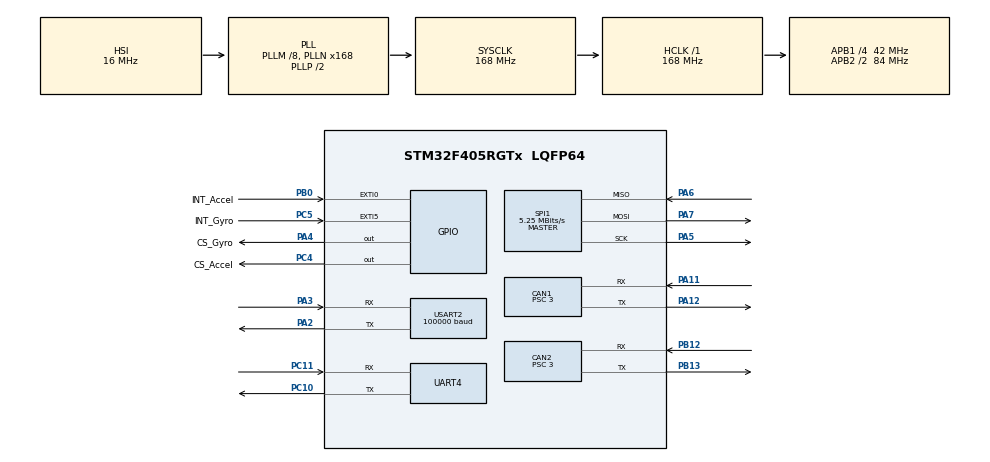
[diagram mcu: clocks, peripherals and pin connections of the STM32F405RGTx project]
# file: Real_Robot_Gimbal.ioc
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CAN1.ABOM=ENABLE
CAN1.AWUM=ENABLE
CAN1.AutoBusOff=ENABLE
CAN1.AutoRetransmission=ENABLE
CAN1.BS1=CAN_BS1_10TQ
CAN1.BS2=CAN_BS2_3TQ
CAN1.CalculateBaudRate=1000000
CAN1.CalculateTimeBit=1000
CAN1.CalculateTimeQuantum=71.42857142857143
CAN1.NART=ENABLE
CAN1.Prescaler=3
CAN1.SJW=CAN_SJW_2TQ
CAN2.AutoBusOff=ENABLE
CAN2.AutoRetransmission=ENABLE
CAN2.BS1=CAN_BS1_10TQ
CAN2.BS2=CAN_BS2_3TQ
CAN2.CalculateBaudRate=1000000
CAN2.CalculateTimeBit=1000
CAN2.CalculateTimeQuantum=71.42857142857143
CAN2.Prescaler=3
CAN2.SJW=CAN_SJW_2TQ
Dma.Request0=USART2_RX
Dma.Request1=USART2_TX
Dma.Request2=SPI1_RX
Dma.Request3=UART4_RX
Dma.Request4=UART4_TX
Dma.Request5=SPI1_TX
Dma.SPI1_RX.2.Direction=DMA_PERIPH_TO_MEMORY
Dma.SPI1_RX.2.FIFOMode=DMA_FIFOMODE_DISABLE
Dma.SPI1_RX.2.Instance=DMA2_Stream0
Dma.SPI1_RX.2.MemDataAlignment=DMA_MDATAALIGN_BYTE
Dma.SPI1_RX.2.MemInc=DMA_MINC_ENABLE
Dma.SPI1_RX.2.Mode=DMA_NORMAL
Dma.SPI1_RX.2.PeriphDataAlignment=DMA_PDATAALIGN_BYTE
Dma.SPI1_RX.2.PeriphInc=DMA_PINC_DISABLE
Dma.SPI1_RX.2.Priority=DMA_PRIORITY_LOW
Dma.SPI1_TX.5.Direction=DMA_MEMORY_TO_PERIPH
Dma.SPI1_TX.5.FIFOMode=DMA_FIFOMODE_DISABLE
Dma.SPI1_TX.5.Instance=DMA2_Stream3
Dma.SPI1_TX.5.MemDataAlignment=DMA_MDATAALIGN_BYTE
Dma.SPI1_TX.5.MemInc=DMA_MINC_ENABLE
Dma.SPI1_TX.5.Mode=DMA_NORMAL
Dma.SPI1_TX.5.PeriphDataAlignment=DMA_PDATAALIGN_BYTE
Dma.SPI1_TX.5.PeriphInc=DMA_PINC_DISABLE
Dma.SPI1_TX.5.Priority=DMA_PRIORITY_LOW
Dma.UART4_RX.3.Direction=DMA_PERIPH_TO_MEMORY
Dma.UART4_RX.3.FIFOMode=DMA_FIFOMODE_DISABLE
Dma.UART4_RX.3.Instance=DMA1_Stream2
Dma.UART4_RX.3.MemDataAlignment=DMA_MDATAALIGN_BYTE
Dma.UART4_RX.3.MemInc=DMA_MINC_ENABLE
Dma.UART4_RX.3.Mode=DMA_NORMAL
Dma.UART4_RX.3.PeriphDataAlignment=DMA_PDATAALIGN_BYTE
Dma.UART4_RX.3.PeriphInc=DMA_PINC_DISABLE
Dma.UART4_RX.3.Priority=DMA_PRIORITY_LOW
Dma.UART4_TX.4.Direction=DMA_MEMORY_TO_PERIPH
Dma.UART4_TX.4.FIFOMode=DMA_FIFOMODE_DISABLE
Dma.UART4_TX.4.Instance=DMA1_Stream4
Dma.UART4_TX.4.MemDataAlignment=DMA_MDATAALIGN_BYTE
Dma.UART4_TX.4.MemInc=DMA_MINC_ENABLE
Dma.UART4_TX.4.Mode=DMA_NORMAL
Dma.UART4_TX.4.PeriphDataAlignment=DMA_PDATAALIGN_BYTE
Dma.UART4_TX.4.PeriphInc=DMA_PINC_DISABLE
Dma.UART4_TX.4.Priority=DMA_PRIORITY_LOW
Dma.USART2_RX.0.Direction=DMA_PERIPH_TO_MEMORY
Dma.USART2_RX.0.FIFOMode=DMA_FIFOMODE_DISABLE
Dma.USART2_RX.0.Instance=DMA1_Stream5
Dma.USART2_RX.0.MemDataAlignment=DMA_MDATAALIGN_BYTE
Dma.USART2_RX.0.MemInc=DMA_MINC_ENABLE
Dma.USART2_RX.0.Mode=DMA_NORMAL
Dma.USART2_RX.0.PeriphDataAlignment=DMA_PDATAALIGN_BYTE
Dma.USART2_RX.0.PeriphInc=DMA_PINC_DISABLE
Dma.USART2_RX.0.Priority=DMA_PRIORITY_LOW
Dma.USART2_TX.1.Direction=DMA_MEMORY_TO_PERIPH
Dma.USART2_TX.1.FIFOMode=DMA_FIFOMODE_DISABLE
Dma.USART2_TX.1.Instance=DMA1_Stream6
Dma.USART2_TX.1.MemDataAlignment=DMA_MDATAALIGN_BYTE
Dma.USART2_TX.1.MemInc=DMA_MINC_ENABLE
Dma.USART2_TX.1.Mode=DMA_NORMAL
Dma.USART2_TX.1.PeriphDataAlignment=DMA_PDATAALIGN_BYTE
Dma.USART2_TX.1.PeriphInc=DMA_PINC_DISABLE
Dma.USART2_TX.1.Priority=DMA_PRIORITY_LOW
FREERTOS.BinarySemaphores01=wake_launch,Dynamic,NULL,Not Available;wake_launch_motor,Dynamic,NULL,Not Available
FREERTOS.Queues01=Target_Angle,8,TargetAngleMessage_t,0,Dynamic,NULL,NULL;Update_PID_para,8,PidParameterUpdate_t,0,Dynamic,NULL,NULL;Update_launch_para,4,LaunchParameterUpdate_t,0,Dynamic,NULL,NULL
FREERTOS.Tasks01=defaultTask,24,128,StartDefaultTask,Default,NULL,Dynamic,NULL,NULL;Process_Data,9,512,Data_Process,As weak,NULL,Dynamic,NULL,NULL;PID,24,512,PID_calc,As weak,NULL,Dynamic,NULL,NULL;vofa,8,256,VOFA_print,As weak,NULL,Dynamic,NULL,NULL;launch,24,128,Launch_Task,As weak,NULL,Dynamic,NULL,NULL
Mcu.Family=STM32F4
Mcu.Name=STM32F405RGTx
Mcu.Package=LQFP64
NVIC.CAN1_RX0_IRQn=true\:5\:0\:false\:false\:true\:true\:true\:true\:true
NVIC.CAN2_RX0_IRQn=true\:5\:0\:false\:false\:true\:true\:true\:true\:true
NVIC.DMA1_Stream2_IRQn=true\:5\:0\:false\:false\:true\:true\:false\:true\:true
NVIC.DMA1_Stream4_IRQn=true\:5\:0\:false\:false\:true\:true\:false\:true\:true
NVIC.DMA1_Stream5_IRQn=true\:5\:0\:false\:false\:true\:true\:false\:true\:true
NVIC.DMA1_Stream6_IRQn=true\:5\:0\:false\:false\:true\:true\:false\:true\:true
NVIC.DMA2_Stream0_IRQn=true\:5\:0\:false\:false\:true\:true\:false\:true\:true
NVIC.DMA2_Stream3_IRQn=true\:5\:0\:false\:false\:true\:true\:false\:true\:true
NVIC.EXTI0_IRQn=true\:5\:0\:false\:false\:true\:true\:true\:true\:true
NVIC.EXTI9_5_IRQn=true\:5\:0\:false\:false\:true\:true\:true\:true\:true
NVIC.PriorityGroup=NVIC_PRIORITYGROUP_4
NVIC.TIM1_UP_TIM10_IRQn=true\:15\:0\:false\:false\:true\:false\:false\:true\:true
NVIC.TimeBase=TIM1_UP_TIM10_IRQn
NVIC.TimeBaseIP=TIM1
NVIC.UART4_IRQn=true\:5\:0\:false\:false\:true\:true\:false\:true\:true
NVIC.USART2_IRQn=true\:5\:0\:false\:false\:true\:true\:false\:true\:true
PA11.Mode=CAN_Activate
PA11.Signal=CAN1_RX
PA12.Mode=CAN_Activate
PA12.Signal=CAN1_TX
PA13.Mode=Serial_Wire
PA13.Signal=SYS_JTMS-SWDIO
PA14.Mode=Serial_Wire
PA14.Signal=SYS_JTCK-SWCLK
PA2.Mode=Asynchronous
PA2.Signal=USART2_TX
PA3.Mode=Asynchronous
PA3.Signal=USART2_RX
PA4.GPIO_Label=CS_Gyro
PA4.PinState=GPIO_PIN_SET
PA4.Signal=GPIO_Output
PA5.Mode=Full_Duplex_Master
PA5.Signal=SPI1_SCK
PA6.Mode=Full_Duplex_Master
PA6.Signal=SPI1_MISO
PA7.Mode=Full_Duplex_Master
PA7.Signal=SPI1_MOSI
PB0.GPIO_Label=INT_Accel
PB0.GPIO_ModeDefaultEXTI=GPIO_MODE_IT_RISING
PB0.Signal=GPXTI0
PB12.Mode=CAN_Activate
PB12.Signal=CAN2_RX
PB13.Mode=CAN_Activate
PB13.Signal=CAN2_TX
PC10.Mode=Asynchronous
PC10.Signal=UART4_TX
PC11.Mode=Asynchronous
PC11.Signal=UART4_RX
PC4.GPIO_Label=CS_Accel
PC4.PinState=GPIO_PIN_SET
PC4.Signal=GPIO_Output
PC5.GPIO_Label=INT_Gyro
PC5.GPIO_ModeDefaultEXTI=GPIO_MODE_IT_RISING
PC5.Signal=GPXTI5
PH0-OSC_IN.Mode=HSE-External-Oscillator
PH0-OSC_IN.Signal=RCC_OSC_IN
PH1-OSC_OUT.Mode=HSE-External-Oscillator
PH1-OSC_OUT.Signal=RCC_OSC_OUT
ProjectManager.HeapSize=0x200
ProjectManager.StackSize=0x400
ProjectManager.TargetToolchain=MDK-ARM V5.32
RCC.48MHZClocksFreq_Value=84000000
RCC.AHBFreq_Value=168000000
RCC.APB1CLKDivider=RCC_HCLK_DIV4
RCC.APB1Freq_Value=42000000
RCC.APB1TimFreq_Value=84000000
RCC.APB2CLKDivider=RCC_HCLK_DIV2
RCC.APB2Freq_Value=84000000
RCC.APB2TimFreq_Value=168000000
RCC.CortexFreq_Value=168000000
RCC.HCLKFreq_Value=168000000
RCC.HSE_VALUE=25000000
RCC.HSI_VALUE=16000000
RCC.LSE_VALUE=32768
RCC.PLLM=8
RCC.PLLN=168
RCC.SYSCLKFreq_VALUE=168000000
RCC.SYSCLKSource=RCC_SYSCLKSOURCE_PLLCLK
RCC.VCOOutputFreq_Value=336000000
SPI1.BaudRatePrescaler=SPI_BAUDRATEPRESCALER_16
SPI1.CLKPhase=SPI_PHASE_2EDGE
SPI1.CLKPolarity=SPI_POLARITY_HIGH
SPI1.CalculateBaudRate=5.25 MBits/s
SPI1.Direction=SPI_DIRECTION_2LINES
SPI1.Mode=SPI_MODE_MASTER
SPI1.VirtualType=VM_MASTER
UART4.VirtualMode=Asynchronous
USART2.BaudRate=100000
USART2.Parity=PARITY_EVEN
USART2.StopBits=STOPBITS_2
USART2.VirtualMode=VM_ASYNC
USART2.WordLength=WORDLENGTH_9B
VP_FREERTOS_VS_CMSIS_V2.Mode=CMSIS_V2
VP_SYS_VS_tim1.Mode=TIM1
board=custom

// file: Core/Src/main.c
/* USER CODE BEGIN Header */
/**
  ******************************************************************************
  * @file           : main.c
  * @brief          : Main program body
  ******************************************************************************
  * @attention
  *
  * Copyright (c) 2026 STMicroelectronics.
  * All rights reserved.
  *
  * This software is licensed under terms that can be found in the LICENSE file
  * in the root directory of this software component.
  * If no LICENSE file comes with this software, it is provided AS-IS.
  *
  ******************************************************************************
  */
/* USER CODE END Header */
#include "main.h"
#include "cmsis_os.h"
#include "can.h"
#include "dma.h"
#include "spi.h"
#include "usart.h"
#include "gpio.h"

/* USER CODE BEGIN Includes */
#include "hardware_drivers.h"
/* USER CODE END Includes */

void SystemClock_Config(void);
void MX_FREERTOS_Init(void);

int main(void)
{

  /* MCU Configuration--------------------------------------------------------*/

  /* Reset of all peripherals, Initializes the Flash interface and the Systick. */
	HAL_Init();

  /* Configure the system clock */
  SystemClock_Config();

  /* Initialize all configured peripherals */
  MX_GPIO_Init();
  MX_DMA_Init();
  MX_USART2_UART_Init();
  MX_CAN1_Init();
  MX_CAN2_Init();
  MX_SPI1_Init();
  MX_UART4_Init();
  /* USER CODE BEGIN 2 */
  if (HardwareDrivers_Init() != HAL_OK)
  {
    Error_Handler();
  }
  /* USER CODE END 2 */

  /* Init scheduler */
  osKernelInitialize();  /* Call init function for freertos objects (in cmsis_os2.c) */
  MX_FREERTOS_Init();

  /* Start scheduler */
  osKernelStart();

  /* We should never get here as control is now taken by the scheduler */

  /* Infinite loop */
  while (1)
  {

  }
}

void SystemClock_Config(void)
{
  RCC_OscInitTypeDef RCC_OscInitStruct = {0};
  RCC_ClkInitTypeDef RCC_ClkInitStruct = {0};

  /** Configure the main internal regulator output voltage
  */
  __HAL_RCC_PWR_CLK_ENABLE();
  __HAL_PWR_VOLTAGESCALING_CONFIG(PWR_REGULATOR_VOLTAGE_SCALE1);

  /** Initializes the RCC Oscillators according to the specified parameters
  * in the RCC_OscInitTypeDef structure.
  */
  RCC_OscInitStruct.OscillatorType = RCC_OSCILLATORTYPE_HSI;
  RCC_OscInitStruct.HSIState = RCC_HSI_ON;
  RCC_OscInitStruct.HSICalibrationValue = RCC_HSICALIBRATION_DEFAULT;
  RCC_OscInitStruct.PLL.PLLState = RCC_PLL_ON;
  RCC_OscInitStruct.PLL.PLLSource = RCC_PLLSOURCE_HSI;
  RCC_OscInitStruct.PLL.PLLM = 8;
  RCC_OscInitStruct.PLL.PLLN = 168;
  RCC_OscInitStruct.PLL.PLLP = RCC_PLLP_DIV2;
  RCC_OscInitStruct.PLL.PLLQ = 4;
  if (HAL_RCC_OscConfig(&RCC_OscInitStruct) != HAL_OK)
  {
    Error_Handler();
  }

  /** Initializes the CPU, AHB and APB buses clocks
  */
  RCC_ClkInitStruct.ClockType = RCC_CLOCKTYPE_HCLK|RCC_CLOCKTYPE_SYSCLK
                              |RCC_CLOCKTYPE_PCLK1|RCC_CLOCKTYPE_PCLK2;
  RCC_ClkInitStruct.SYSCLKSource = RCC_SYSCLKSOURCE_PLLCLK;
  RCC_ClkInitStruct.AHBCLKDivider = RCC_SYSCLK_DIV1;
  RCC_ClkInitStruct.APB1CLKDivider = RCC_HCLK_DIV4;
  RCC_ClkInitStruct.APB2CLKDivider = RCC_HCLK_DIV2;

  if (HAL_RCC_ClockConfig(&RCC_ClkInitStruct, FLASH_LATENCY_5) != HAL_OK)
  {
    Error_Handler();
  }
}

void HAL_TIM_PeriodElapsedCallback(TIM_HandleTypeDef *htim)
{
  if (htim->Instance == TIM1)
  {
    HAL_IncTick();
  }
}

void Error_Handler(void)
{
  __disable_irq();
  while (1)
  {
  }
}

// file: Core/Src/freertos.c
/* USER CODE BEGIN Header */
/**
  ******************************************************************************
  * File Name          : freertos.c
  * Description        : Code for freertos applications
  ******************************************************************************
  * @attention
  *
  * Copyright (c) 2026 STMicroelectronics.
  * All rights reserved.
  *
  * This software is licensed under terms that can be found in the LICENSE file
  * in the root directory of this software component.
  * If no LICENSE file comes with this software, it is provided AS-IS.
  *
  ******************************************************************************
  */
/* USER CODE END Header */

#include "FreeRTOS.h"
#include "task.h"
#include "main.h"
#include "cmsis_os.h"

/* USER CODE BEGIN Includes */
#include "gimbal_control.h"
/* USER CODE END Includes */

/* Definitions for defaultTask */
osThreadId_t defaultTaskHandle;
const osThreadAttr_t defaultTask_attributes = {
  .name = "defaultTask",
  .stack_size = 256 * 4,
  .priority = (osPriority_t) osPriorityNormal,
};
/* Definitions for Process_Data */
osThreadId_t Process_DataHandle;
const osThreadAttr_t Process_Data_attributes = {
  .name = "Process_Data",
  .stack_size = 512 * 4,
  .priority = (osPriority_t) osPriorityLow1,
};
/* Definitions for PID */
osThreadId_t PIDHandle;
const osThreadAttr_t PID_attributes = {
  .name = "PID",
  .stack_size = 1024 * 4,   /* PID_calc 局部变量多，2KB 偏紧易溢出导致 CAN 发送卡死+疯转 */
  .priority = (osPriority_t) osPriorityNormal,
};
/* Definitions for vofa */
osThreadId_t vofaHandle;
const osThreadAttr_t vofa_attributes = {
  .name = "vofa",
  .stack_size = 512 * 4,
  .priority = (osPriority_t) osPriorityLow,
};
/* Definitions for launch */
osThreadId_t launchHandle;
const osThreadAttr_t launch_attributes = {
  .name = "launch",
  .stack_size = 512 * 4,   /* 1KB 仍偏小，加到 2KB 防 launch 卡死(表现为 M2006 不更新+电机疯转) */
  .priority = (osPriority_t) osPriorityNormal,
};
/* Definitions for Target_Angle */
osMessageQueueId_t Target_AngleHandle;
const osMessageQueueAttr_t Target_Angle_attributes = {
  .name = "Target_Angle"
};
/* Definitions for Update_PID_para */
osMessageQueueId_t Update_PID_paraHandle;
const osMessageQueueAttr_t Update_PID_para_attributes = {
  .name = "Update_PID_para"
};
/* Definitions for Update_launch_para */
osMessageQueueId_t Update_launch_paraHandle;
const osMessageQueueAttr_t Update_launch_para_attributes = {
  .name = "Update_launch_para"
};
/* Definitions for wake_launch */
osSemaphoreId_t wake_launchHandle;
const osSemaphoreAttr_t wake_launch_attributes = {
  .name = "wake_launch"
};
/* Definitions for wake_launch_motor */
osSemaphoreId_t wake_launch_motorHandle;
const osSemaphoreAttr_t wake_launch_motor_attributes = {
  .name = "wake_launch_motor"
};

void StartDefaultTask(void *argument);
void Data_Process(void *argument);
void PID_calc(void *argument);
void VOFA_print(void *argument);
void Launch_Task(void *argument);

void MX_FREERTOS_Init(void); /* (MISRA C 2004 rule 8.1) */

void MX_FREERTOS_Init(void) {

  /* Create the semaphores(s) */
  /* creation of wake_launch */
  wake_launchHandle = osSemaphoreNew(1, 0, &wake_launch_attributes);

  /* creation of wake_launch_motor */
  wake_launch_motorHandle = osSemaphoreNew(1, 0, &wake_launch_motor_attributes);

  /* Create the queue(s) */
  /* creation of Target_Angle */
  Target_AngleHandle = osMessageQueueNew (8, sizeof(TargetAngleMessage_t), &Target_Angle_attributes);

  /* creation of Update_PID_para */
  Update_PID_paraHandle = osMessageQueueNew (8, sizeof(PidParameterUpdate_t), &Update_PID_para_attributes);

  /* creation of Update_launch_para */
  Update_launch_paraHandle = osMessageQueueNew (4, sizeof(LaunchParameterUpdate_t), &Update_launch_para_attributes);

  /* Create the thread(s) */
  /* creation of defaultTask */
  defaultTaskHandle = osThreadNew(StartDefaultTask, NULL, &defaultTask_attributes);

  /* creation of Process_Data */
  Process_DataHandle = osThreadNew(Data_Process, NULL, &Process_Data_attributes);

  /* creation of PID */
  PIDHandle = osThreadNew(PID_calc, NULL, &PID_attributes);

  /* creation of vofa */
  vofaHandle = osThreadNew(VOFA_print, NULL, &vofa_attributes);

  /* creation of launch */
  launchHandle = osThreadNew(Launch_Task, NULL, &launch_attributes);

}

void StartDefaultTask(void *argument)
{
  for(;;)
  {
    osDelay(1);
  }
}

__weak void Data_Process(void *argument)
{
  for(;;)
  {
    osDelay(1);
  }
}

__weak void PID_calc(void *argument)
{
  for(;;)
  {
    osDelay(1);
  }
}

__weak void VOFA_print(void *argument)
{
  for(;;)
  {
    osDelay(1);
  }
}

__weak void Launch_Task(void *argument)
{
  for(;;)
  {
    osDelay(1);
  }
}
